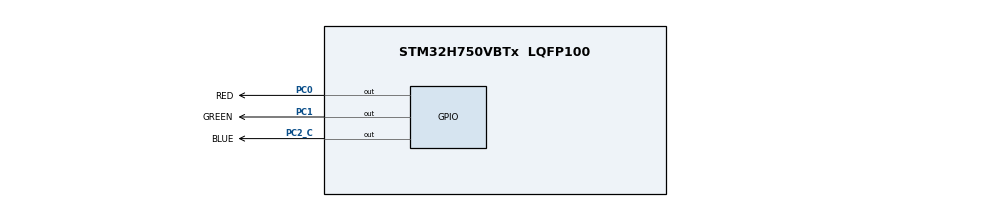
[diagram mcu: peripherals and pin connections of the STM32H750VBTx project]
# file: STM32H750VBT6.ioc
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CORTEX_M7.CPU_DCache=Enabled
CORTEX_M7.CPU_ICache=Enabled
CORTEX_M7.MPU_Control=__NULL
Mcu.Family=STM32H7
Mcu.Name=STM32H750VBTx
Mcu.Package=LQFP100
NVIC.PriorityGroup=NVIC_PRIORITYGROUP_4
PA13\ (JTMS/SWDIO).Mode=Serial_Wire
PA13\ (JTMS/SWDIO).Signal=DEBUG_JTMS-SWDIO
PA14\ (JTCK/SWCLK).Mode=Serial_Wire
PA14\ (JTCK/SWCLK).Signal=DEBUG_JTCK-SWCLK
PC0.GPIO_Label=RED
PC0.GPIO_PuPd=GPIO_PULLUP
PC0.PinState=GPIO_PIN_SET
PC0.Signal=GPIO_Output
PC1.GPIO_Label=GREEN
PC1.GPIO_PuPd=GPIO_PULLUP
PC1.GPIO_Speed=GPIO_SPEED_FREQ_LOW
PC1.PinState=GPIO_PIN_SET
PC1.Signal=GPIO_Output
PC14-OSC32_IN\ (OSC32_IN).Mode=LSE-External-Oscillator
PC14-OSC32_IN\ (OSC32_IN).Signal=RCC_OSC32_IN
PC15-OSC32_OUT\ (OSC32_OUT).Mode=LSE-External-Oscillator
PC15-OSC32_OUT\ (OSC32_OUT).Signal=RCC_OSC32_OUT
PC2_C.GPIO_Label=BLUE
PC2_C.GPIO_PuPd=GPIO_PULLUP
PC2_C.PinState=GPIO_PIN_SET
PC2_C.Signal=GPIO_Output
PH0-OSC_IN\ (PH0).Mode=HSE-External-Oscillator
PH0-OSC_IN\ (PH0).Signal=RCC_OSC_IN
PH1-OSC_OUT\ (PH1).Mode=HSE-External-Oscillator
PH1-OSC_OUT\ (PH1).Signal=RCC_OSC_OUT
ProjectManager.HeapSize=0x800
ProjectManager.StackSize=0x800
ProjectManager.TargetToolchain=MDK-ARM V5
RCC.ADCFreq_Value=24187500
RCC.APB1Freq_Value=120000000
RCC.APB2Freq_Value=120000000
RCC.APB3Freq_Value=120000000
RCC.APB4Freq_Value=120000000
RCC.CortexFreq_Value=480000000
RCC.D1PPRE=RCC_APB3_DIV2
RCC.D2PPRE1=RCC_APB1_DIV2
RCC.D2PPRE2=RCC_APB2_DIV2
RCC.D3PPRE=RCC_APB4_DIV2
RCC.DIVM1=1
RCC.DIVN1=80
RCC.FLatency=FLASH_LATENCY_4
RCC.HCLKFreq_Value=240000000
RCC.HPRE=RCC_HCLK_DIV2
RCC.HSE_VALUE=12000000
RCC.PLLFRACN=0
RCC.PLLSourceVirtual=RCC_PLLSOURCE_HSE
RCC.PWR_Regulator_Voltage_Scale=PWR_REGULATOR_VOLTAGE_SCALE0
RCC.ProductRev=revV
RCC.SYSCLKFreq_VALUE=480000000
RCC.SYSCLKSource=RCC_SYSCLKSOURCE_PLLCLK
RCC.USBFreq_Value=480000000
board=custom

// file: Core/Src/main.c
/* USER CODE BEGIN Header */
/**
  ******************************************************************************
  * @file           : main.c
  * @brief          : Main program body
  ******************************************************************************
  * @attention
  *
  * <h2><center>&copy; Copyright (c) 2021 STMicroelectronics.
  * All rights reserved.</center></h2>
  *
  * This software component is licensed by ST under BSD 3-Clause license,
  * the "License"; You may not use this file except in compliance with the
  * License. You may obtain a copy of the License at:
  *                        opensource.org/licenses/BSD-3-Clause
  *
  ******************************************************************************
  */
/* USER CODE END Header */
#include "main.h"
#include "gpio.h"

/* USER CODE BEGIN Includes */
#include "BSP_GPIO.h"
/* USER CODE END Includes */

void SystemClock_Config(void);

int main(void)
{
  /* USER CODE BEGIN 1 */
	u8 color = 0;
  /* USER CODE END 1 */

  /* Enable I-Cache---------------------------------------------------------*/
  SCB_EnableICache();

  /* Enable D-Cache---------------------------------------------------------*/
  SCB_EnableDCache();

  /* MCU Configuration--------------------------------------------------------*/

  /* Reset of all peripherals, Initializes the Flash interface and the Systick. */
  HAL_Init();

  /* Configure the system clock */
  SystemClock_Config();

  /* Initialize all configured peripherals */
  MX_GPIO_Init();

  /* Infinite loop */
  /* USER CODE BEGIN WHILE */
  while (1)
  {
		switch(color%7)
		{
			case 0:
				LED_R(0);
				LED_G(1);
				LED_B(1);
				break;
			case 1:
				LED_R(1);
				LED_G(0);
				LED_B(1);
				break;
			case 2:
				LED_R(1);
				LED_G(1);
				LED_B(0);
				break;
			case 3:
				LED_R(0);
				LED_G(0);
				LED_B(1);
				break;
			case 4:
				LED_R(0);
				LED_G(1);
				LED_B(0);
				break;
			case 5:
				LED_R(1);
				LED_G(0);
				LED_B(0);
				break;
			case 6:
				LED_R(0);
				LED_G(0);
				LED_B(0);
				break;
			default:
				break;
		}
		color++;

		HAL_Delay(1000);
    /* USER CODE END WHILE */

  }
}

void SystemClock_Config(void)
{
  RCC_OscInitTypeDef RCC_OscInitStruct = {0};
  RCC_ClkInitTypeDef RCC_ClkInitStruct = {0};

  /** Supply configuration update enable
  */
  HAL_PWREx_ConfigSupply(PWR_LDO_SUPPLY);
  /** Configure the main internal regulator output voltage
  */
  __HAL_PWR_VOLTAGESCALING_CONFIG(PWR_REGULATOR_VOLTAGE_SCALE0);

  while(!__HAL_PWR_GET_FLAG(PWR_FLAG_VOSRDY)) {}
  /** Initializes the RCC Oscillators according to the specified parameters
  * in the RCC_OscInitTypeDef structure.
  */
  RCC_OscInitStruct.OscillatorType = RCC_OSCILLATORTYPE_HSE;
  RCC_OscInitStruct.HSEState = RCC_HSE_ON;
  RCC_OscInitStruct.PLL.PLLState = RCC_PLL_ON;
  RCC_OscInitStruct.PLL.PLLSource = RCC_PLLSOURCE_HSE;
  RCC_OscInitStruct.PLL.PLLM = 1;
  RCC_OscInitStruct.PLL.PLLN = 80;
  RCC_OscInitStruct.PLL.PLLP = 2;
  RCC_OscInitStruct.PLL.PLLQ = 2;
  RCC_OscInitStruct.PLL.PLLR = 2;
  RCC_OscInitStruct.PLL.PLLRGE = RCC_PLL1VCIRANGE_3;
  RCC_OscInitStruct.PLL.PLLVCOSEL = RCC_PLL1VCOWIDE;
  RCC_OscInitStruct.PLL.PLLFRACN = 0;
  if (HAL_RCC_OscConfig(&RCC_OscInitStruct) != HAL_OK)
  {
    Error_Handler();
  }
  /** Initializes the CPU, AHB and APB buses clocks
  */
  RCC_ClkInitStruct.ClockType = RCC_CLOCKTYPE_HCLK|RCC_CLOCKTYPE_SYSCLK
                              |RCC_CLOCKTYPE_PCLK1|RCC_CLOCKTYPE_PCLK2
                              |RCC_CLOCKTYPE_D3PCLK1|RCC_CLOCKTYPE_D1PCLK1;
  RCC_ClkInitStruct.SYSCLKSource = RCC_SYSCLKSOURCE_PLLCLK;
  RCC_ClkInitStruct.SYSCLKDivider = RCC_SYSCLK_DIV1;
  RCC_ClkInitStruct.AHBCLKDivider = RCC_HCLK_DIV2;
  RCC_ClkInitStruct.APB3CLKDivider = RCC_APB3_DIV2;
  RCC_ClkInitStruct.APB1CLKDivider = RCC_APB1_DIV2;
  RCC_ClkInitStruct.APB2CLKDivider = RCC_APB2_DIV2;
  RCC_ClkInitStruct.APB4CLKDivider = RCC_APB4_DIV2;

  if (HAL_RCC_ClockConfig(&RCC_ClkInitStruct, FLASH_LATENCY_4) != HAL_OK)
  {
    Error_Handler();
  }
}

void Error_Handler(void)
{
  __disable_irq();
  while (1)
  {
  }
}

/************************ (C) COPYRIGHT STMicroelectronics *****END OF FILE****/
